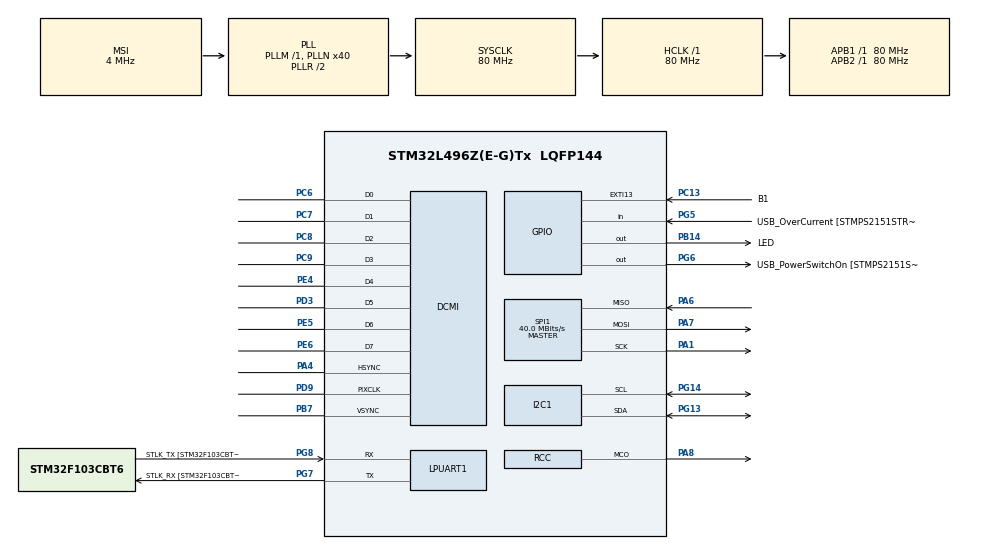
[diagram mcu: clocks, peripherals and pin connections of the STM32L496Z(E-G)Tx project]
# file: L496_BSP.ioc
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DCMI.JPEGMode=DCMI_JPEG_ENABLE
DCMI.PCKPolarity=DCMI_PCKPOLARITY_RISING
DCMI.VSPolarity=DCMI_VSPOLARITY_LOW
Dma.DCMI.0.Direction=DMA_PERIPH_TO_MEMORY
Dma.DCMI.0.Instance=DMA2_Channel5
Dma.DCMI.0.MemDataAlignment=DMA_MDATAALIGN_WORD
Dma.DCMI.0.MemInc=DMA_MINC_ENABLE
Dma.DCMI.0.Mode=DMA_NORMAL
Dma.DCMI.0.PeriphDataAlignment=DMA_PDATAALIGN_WORD
Dma.DCMI.0.PeriphInc=DMA_PINC_DISABLE
Dma.DCMI.0.Priority=DMA_PRIORITY_HIGH
Dma.Request0=DCMI
I2C1.Timeout=0x000081E8
I2C1.Timing=0x10909CEC
Mcu.Family=STM32L4
Mcu.Name=STM32L496Z(E-G)Tx
Mcu.Package=LQFP144
NVIC.DCMI_IRQn=true\:0\:0\:false\:false\:true\:true\:true
NVIC.DMA2_Channel5_IRQn=true\:0\:0\:false\:false\:true\:false\:true
NVIC.PriorityGroup=NVIC_PRIORITYGROUP_4
PA1.Mode=Full_Duplex_Master
PA1.Signal=SPI1_SCK
PA13\ (JTMS/SWDIO).GPIO_Label=TMS
PA13\ (JTMS/SWDIO).Mode=Trace_Asynchronous_SW
PA13\ (JTMS/SWDIO).Signal=SYS_JTMS-SWDIO
PA14\ (JTCK/SWCLK).GPIO_Label=TCK
PA14\ (JTCK/SWCLK).Mode=Trace_Asynchronous_SW
PA14\ (JTCK/SWCLK).Signal=SYS_JTCK-SWCLK
PA4.GPIO_PuPd=GPIO_PULLUP
PA4.GPIO_Speed=GPIO_SPEED_FREQ_VERY_HIGH
PA4.Mode=Slave_8_bits_External_Synchro
PA4.Signal=DCMI_HSYNC
PA6.Mode=Full_Duplex_Master
PA6.Signal=SPI1_MISO
PA7.Mode=Full_Duplex_Master
PA7.Signal=SPI1_MOSI
PA8.Mode=Clock-out
PA8.Signal=RCC_MCO
PB14.GPIO_Label=LED
PB14.GPIO_ModeDefaultOutputPP=GPIO_MODE_OUTPUT_PP
PB14.PinState=GPIO_PIN_RESET
PB14.Signal=GPIO_Output
PB3\ (JTDO/TRACESWO).GPIO_Label=SWO
PB3\ (JTDO/TRACESWO).Mode=Trace_Asynchronous_SW
PB3\ (JTDO/TRACESWO).Signal=SYS_JTDO-SWO
PB7.GPIO_PuPd=GPIO_PULLUP
PB7.GPIO_Speed=GPIO_SPEED_FREQ_VERY_HIGH
PB7.Mode=Slave_8_bits_External_Synchro
PB7.Signal=DCMI_VSYNC
PC13.GPIO_Label=B1
PC13.Signal=GPXTI13
PC6.GPIO_PuPd=GPIO_PULLUP
PC6.GPIO_Speed=GPIO_SPEED_FREQ_VERY_HIGH
PC6.Mode=Slave_8_bits_External_Synchro
PC6.Signal=DCMI_D0
PC7.GPIO_PuPd=GPIO_PULLUP
PC7.GPIO_Speed=GPIO_SPEED_FREQ_VERY_HIGH
PC7.Mode=Slave_8_bits_External_Synchro
PC7.Signal=DCMI_D1
PC8.GPIO_PuPd=GPIO_PULLUP
PC8.GPIO_Speed=GPIO_SPEED_FREQ_VERY_HIGH
PC8.Mode=Slave_8_bits_External_Synchro
PC8.Signal=DCMI_D2
PC9.GPIO_PuPd=GPIO_PULLUP
PC9.GPIO_Speed=GPIO_SPEED_FREQ_VERY_HIGH
PC9.Mode=Slave_8_bits_External_Synchro
PC9.Signal=DCMI_D3
PD3.GPIO_PuPd=GPIO_PULLUP
PD3.GPIO_Speed=GPIO_SPEED_FREQ_VERY_HIGH
PD3.Mode=Slave_8_bits_External_Synchro
PD3.Signal=DCMI_D5
PD9.GPIO_PuPd=GPIO_PULLUP
PD9.GPIO_Speed=GPIO_SPEED_FREQ_VERY_HIGH
PD9.Mode=Slave_8_bits_External_Synchro
PD9.Signal=DCMI_PIXCLK
PE4.GPIO_PuPd=GPIO_PULLUP
PE4.GPIO_Speed=GPIO_SPEED_FREQ_VERY_HIGH
PE4.Mode=Slave_8_bits_External_Synchro
PE4.Signal=DCMI_D4
PE5.GPIO_PuPd=GPIO_PULLUP
PE5.GPIO_Speed=GPIO_SPEED_FREQ_VERY_HIGH
PE5.Mode=Slave_8_bits_External_Synchro
PE5.Signal=DCMI_D6
PE6.GPIO_PuPd=GPIO_PULLUP
PE6.GPIO_Speed=GPIO_SPEED_FREQ_VERY_HIGH
PE6.Mode=Slave_8_bits_External_Synchro
PE6.Signal=DCMI_D7
PG13.Mode=I2C
PG13.Signal=I2C1_SDA
PG14.Mode=I2C
PG14.Signal=I2C1_SCL
PG5.GPIO_Label=USB_OverCurrent [STMPS2151STR_FAULT]
PG5.Signal=GPIO_Input
PG6.GPIO_Label=USB_PowerSwitchOn [STMPS2151STR_EN]
PG6.Signal=GPIO_Output
PG7.GPIO_Label=STLK_RX [STM32F103CBT6_PA3]
PG7.Mode=Asynchronous
PG7.Signal=LPUART1_TX
PG8.GPIO_Label=STLK_TX [STM32F103CBT6_PA2]
PG8.Mode=Asynchronous
PG8.Signal=LPUART1_RX
PH0-OSC_IN\ (PH0).Mode=HSE-External-Oscillator
PH0-OSC_IN\ (PH0).Signal=RCC_OSC_IN
PH1-OSC_OUT\ (PH1).Mode=HSE-External-Oscillator
PH1-OSC_OUT\ (PH1).Signal=RCC_OSC_OUT
ProjectManager.HeapSize=0x200
ProjectManager.StackSize=0x400
ProjectManager.TargetToolchain=MDK-ARM V5.27
RCC.48MHZClocksFreq_Value=24000000
RCC.ADCFreq_Value=48000000
RCC.AHBFreq_Value=80000000
RCC.APB1Freq_Value=80000000
RCC.APB1TimFreq_Value=80000000
RCC.APB2Freq_Value=80000000
RCC.APB2TimFreq_Value=80000000
RCC.CortexFreq_Value=80000000
RCC.HCLKFreq_Value=80000000
RCC.HSE_VALUE=40000000
RCC.HSI48_VALUE=48000000
RCC.HSI_VALUE=16000000
RCC.LSE_VALUE=32768
RCC.MSI_VALUE=4000000
RCC.PLLMUL=RCC_PLL_MUL9
RCC.PLLN=40
RCC.PLLSAI1N=24
RCC.PLLSAI1Q=RCC_PLLQ_DIV4
RCC.PRESCALERUSB=RCC_USBCLKSOURCE_PLL_DIV1_5
RCC.SYSCLKFreq_VALUE=80000000
RCC.SYSCLKSource=RCC_SYSCLKSOURCE_PLLCLK
RCC.SYSCLKSourceVirtual=RCC_SYSCLKSOURCE_PLLCLK
RCC.USBFreq_Value=24000000
RCC.VCOOutputFreq_Value=160000000
SPI1.BaudRatePrescaler=SPI_BAUDRATEPRESCALER_2
SPI1.CalculateBaudRate=40.0 MBits/s
SPI1.Direction=SPI_DIRECTION_2LINES
SPI1.Mode=SPI_MODE_MASTER
SPI1.VirtualType=VM_MASTER
board=NUCLEO-L496ZG

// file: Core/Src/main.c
/* USER CODE BEGIN Header */
/**
  ******************************************************************************
  * @file           : main.c
  * @brief          : Main program body
  ******************************************************************************
  * @attention
  *
  * <h2><center>&copy; Copyright (c) 2020 STMicroelectronics.
  * All rights reserved.</center></h2>
  *
  * This software component is licensed by ST under BSD 3-Clause license,
  * the "License"; You may not use this file except in compliance with the
  * License. You may obtain a copy of the License at:
  *                        opensource.org/licenses/BSD-3-Clause
  *
  **************
	****************************************************************
  */
/* USER CODE END Header */
#include "main.h"
#include "dcmi.h"
#include "dma.h"
#include "i2c.h"
#include "usart.h"
#include "spi.h"
#include "gpio.h"
#include "delay.h"
#include "cmsis_os.h"
#include "nnom.h"
#include "image.h"
#include "weights.h"

   //task1
   #define TASK1_STK_SIZE		256
   void task1(void *pdata);
   osThreadDef(task1, osPriorityNormal, 1, TASK1_STK_SIZE);

   //task2
   #define TASK2_STK_SIZE		256
   void task2(void *pdata);

   osThreadDef(task2, osPriorityNormal, 1, TASK2_STK_SIZE);

nnom_model_t *model;
const char codeLib[] = "@B%8&WM#*oahkbdpqwmZO0QLCJUYXzcvunxrjft/\\|()1{}[]?-_+~<>i!lI;:,\"^`'.   ";
void print_img_nnom(int8_t * buf)
{
    for(int y = 0; y < 28; y++)
	{
        for (int x = 0; x < 28; x++)
		{
            int index =  69 / 127.0 * (127 - buf[y*28+x]);
			if(index > 69) index =69;
			if(index < 0) index = 0;
            printf("%c",codeLib[index]);
			printf("%c",codeLib[index]);
        }
        printf("\n");
    }
}

void mnist_nnom()
{
	uint32_t tick, time;
	uint32_t predic_label;
	float prob;
	int32_t index = 0;

	printf("\nprediction start.. \n");
	//tick = rt_tick_get();

	// copy data and do prediction
	memcpy(nnom_input_data, (int8_t*)&img[index][0], 784);
	nnom_predict(model, &predic_label, &prob);
	//time = rt_tick_get() - tick;

	//print original image to console
	print_img_nnom((int8_t*)&img[index][0]);

	printf("Time: %d tick\n", time);
	printf("Truth label: %d\n", label[index]);
	printf("Predicted label: %d\n", predic_label);
	printf("Probability: %d%%\n", (int)(prob*100));
}

#ifdef NNOM_USING_STATIC_MEMORY
uint8_t static_buf[1024*20];
#endif

   void task1(void *pdata)
   {
      int count = 1;
		  nnom_set_static_buf(static_buf, sizeof(static_buf));
			model = nnom_model_create();
			model_run(model);
			mnist_nnom();
       while(1)
       {
           //printf("\r\nHello world!\r\n###This is task1 ,count is %d \r\n", count++);
           //HAL_GPIO_TogglePin(LED_GPIO_Port,LED_Pin);
					 delay_ms(1000);
       }
   }
   void task2(void *pdata)
   {
       int count = 1;

       while(1)
       {
           //printf("\r\nHello TencentOS !\r\n***This is task2 ,count is %d \r\n", count++);
           osDelay(1000);
       }
   }

void SystemClock_Config(void);

int main(void)
{

  /* MCU Configuration--------------------------------------------------------*/

  /* Reset of all peripherals, Initializes the Flash interface and the Systick. */
  HAL_Init();

  /* Configure the system clock */
  SystemClock_Config();

  /* Initialize all configured peripherals */
  MX_GPIO_Init();
  MX_DMA_Init();
  MX_DCMI_Init();
  MX_I2C1_Init();
  MX_LPUART1_UART_Init();
  MX_SPI1_Init();
  /* USER CODE BEGIN 2 */
  osKernelInitialize(); //TOS Tiny kernel initialize
  osThreadCreate(osThread(task1), NULL);// Create task1
  osThreadCreate(osThread(task2), NULL);// Create task2
  osKernelStart();//Start TOS Tiny
  /* USER CODE END 2 */

  /* Infinite loop */
  while (1)
  {

  }
}

void SystemClock_Config(void)
{
  RCC_OscInitTypeDef RCC_OscInitStruct = {0};
  RCC_ClkInitTypeDef RCC_ClkInitStruct = {0};
  RCC_PeriphCLKInitTypeDef PeriphClkInit = {0};

  /** Initializes the RCC Oscillators according to the specified parameters
  * in the RCC_OscInitTypeDef structure.
  */
  RCC_OscInitStruct.OscillatorType = RCC_OSCILLATORTYPE_MSI;
  RCC_OscInitStruct.MSIState = RCC_MSI_ON;
  RCC_OscInitStruct.MSICalibrationValue = 0;
  RCC_OscInitStruct.MSIClockRange = RCC_MSIRANGE_6;
  RCC_OscInitStruct.PLL.PLLState = RCC_PLL_ON;
  RCC_OscInitStruct.PLL.PLLSource = RCC_PLLSOURCE_MSI;
  RCC_OscInitStruct.PLL.PLLM = 1;
  RCC_OscInitStruct.PLL.PLLN = 40;
  RCC_OscInitStruct.PLL.PLLP = RCC_PLLP_DIV2;
  RCC_OscInitStruct.PLL.PLLQ = RCC_PLLQ_DIV2;
  RCC_OscInitStruct.PLL.PLLR = RCC_PLLR_DIV2;
  if (HAL_RCC_OscConfig(&RCC_OscInitStruct) != HAL_OK)
  {
    Error_Handler();
  }
  /** Initializes the CPU, AHB and APB buses clocks
  */
  RCC_ClkInitStruct.ClockType = RCC_CLOCKTYPE_HCLK|RCC_CLOCKTYPE_SYSCLK
                              |RCC_CLOCKTYPE_PCLK1|RCC_CLOCKTYPE_PCLK2;
  RCC_ClkInitStruct.SYSCLKSource = RCC_SYSCLKSOURCE_PLLCLK;
  RCC_ClkInitStruct.AHBCLKDivider = RCC_SYSCLK_DIV1;
  RCC_ClkInitStruct.APB1CLKDivider = RCC_HCLK_DIV1;
  RCC_ClkInitStruct.APB2CLKDivider = RCC_HCLK_DIV1;

  if (HAL_RCC_ClockConfig(&RCC_ClkInitStruct, FLASH_LATENCY_4) != HAL_OK)
  {
    Error_Handler();
  }
  PeriphClkInit.PeriphClockSelection = RCC_PERIPHCLK_LPUART1|RCC_PERIPHCLK_I2C1;
  PeriphClkInit.Lpuart1ClockSelection = RCC_LPUART1CLKSOURCE_PCLK1;
  PeriphClkInit.I2c1ClockSelection = RCC_I2C1CLKSOURCE_PCLK1;
  if (HAL_RCCEx_PeriphCLKConfig(&PeriphClkInit) != HAL_OK)
  {
    Error_Handler();
  }
  HAL_RCC_MCOConfig(RCC_MCO1, RCC_MCO1SOURCE_SYSCLK, RCC_MCODIV_1);
  /** Configure the main internal regulator output voltage
  */
  if (HAL_PWREx_ControlVoltageScaling(PWR_REGULATOR_VOLTAGE_SCALE1) != HAL_OK)
  {
    Error_Handler();
  }
}

void Error_Handler(void)
{
}

/************************ (C) COPYRIGHT STMicroelectronics *****END OF FILE****/
